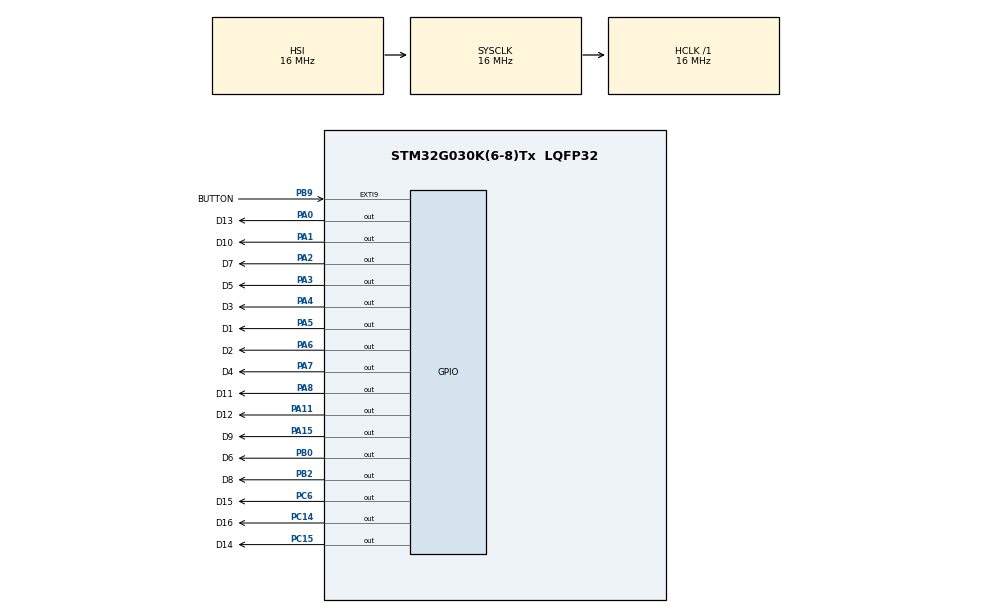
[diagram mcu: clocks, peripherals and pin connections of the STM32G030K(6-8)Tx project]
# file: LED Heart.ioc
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Mcu.Family=STM32G0
Mcu.Name=STM32G030K(6-8)Tx
Mcu.Package=LQFP32
NVIC.EXTI4_15_IRQn=true\:1\:0\:true\:false\:true\:true\:true\:true
NVIC.TIM1_BRK_UP_TRG_COM_IRQn=true\:2\:0\:true\:false\:true\:true\:true\:true
PA0.GPIO_Label=D13
PA0.Signal=GPIO_Output
PA1.GPIO_Label=D10
PA1.Signal=GPIO_Output
PA11\ [PA9].GPIO_Label=D12
PA11\ [PA9].Signal=GPIO_Output
PA15.GPIO_Label=D9
PA15.Signal=GPIO_Output
PA2.GPIO_Label=D7
PA2.Signal=GPIO_Output
PA3.GPIO_Label=D5
PA3.Signal=GPIO_Output
PA4.GPIO_Label=D3
PA4.Signal=GPIO_Output
PA5.GPIO_Label=D1
PA5.Signal=GPIO_Output
PA6.GPIO_Label=D2
PA6.Signal=GPIO_Output
PA7.GPIO_Label=D4
PA7.Signal=GPIO_Output
PA8.GPIO_Label=D11
PA8.Signal=GPIO_Output
PB0.GPIO_Label=D6
PB0.Signal=GPIO_Output
PB2.GPIO_Label=D8
PB2.Signal=GPIO_Output
PB9.GPIO_Label=BUTTON
PB9.GPIO_ModeDefaultEXTI=GPIO_MODE_IT_FALLING
PB9.GPIO_PuPd=GPIO_PULLUP
PB9.Signal=GPXTI9
PC14-OSC32_IN\ (PC14).GPIO_Label=D16
PC14-OSC32_IN\ (PC14).Signal=GPIO_Output
PC15-OSC32_OUT\ (PC15).GPIO_Label=D14
PC15-OSC32_OUT\ (PC15).Signal=GPIO_Output
PC6.GPIO_Label=D15
PC6.Signal=GPIO_Output
ProjectManager.HeapSize=0x200
ProjectManager.StackSize=0x400
ProjectManager.TargetToolchain=STM32CubeIDE
RCC.AHBFreq_Value=16000000
RCC.CortexFreq_Value=16000000
RCC.EXTERNAL_CLOCK_VALUE=12288000
RCC.HCLKFreq_Value=16000000
RCC.HSE_VALUE=8000000
RCC.HSI_VALUE=16000000
RCC.LSE_VALUE=32768
RCC.SYSCLKFreq_VALUE=16000000
RCC.VCOOutputFreq_Value=128000000
TIM1.Period=99
TIM1.Prescaler=15
VP_TIM1_VS_ClockSourceINT.Mode=Internal
board=custom

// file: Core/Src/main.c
/* USER CODE BEGIN Header */
/**
  ******************************************************************************
  * @file           : main.c
  * @brief          : Main program body
  ******************************************************************************
  * @attention
  *
  * Copyright (c) 2026 STMicroelectronics.
  * All rights reserved.
  *
  * This software is licensed under terms that can be found in the LICENSE file
  * in the root directory of this software component.
  * If no LICENSE file comes with this software, it is provided AS-IS.
  *
  ******************************************************************************
  */
/* USER CODE END Header */
#include "main.h"
#include "tim.h"
#include "gpio.h"

/* USER CODE BEGIN Includes */
#include "led_effect.h"
/* USER CODE END Includes */

void SystemClock_Config(void);

int main(void)
{

  /* MCU Configuration--------------------------------------------------------*/

  /* Reset of all peripherals, Initializes the Flash interface and the Systick. */
  HAL_Init();

  /* Configure the system clock */
  SystemClock_Config();

  /* Initialize all configured peripherals */
  MX_GPIO_Init();
  MX_TIM1_Init();
  /* USER CODE BEGIN 2 */
  HAL_TIM_Base_Start_IT(&htim1);
  /* USER CODE END 2 */

  /* Infinite loop */
  /* USER CODE BEGIN WHILE */
  while (1)
  {
	LED_Process_State();
	LED_Handler();

    /* USER CODE END WHILE */

  }
}

void SystemClock_Config(void)
{
  RCC_OscInitTypeDef RCC_OscInitStruct = {0};
  RCC_ClkInitTypeDef RCC_ClkInitStruct = {0};

  /** Configure the main internal regulator output voltage
  */
  HAL_PWREx_ControlVoltageScaling(PWR_REGULATOR_VOLTAGE_SCALE1);

  /** Initializes the RCC Oscillators according to the specified parameters
  * in the RCC_OscInitTypeDef structure.
  */
  RCC_OscInitStruct.OscillatorType = RCC_OSCILLATORTYPE_HSI;
  RCC_OscInitStruct.HSIState = RCC_HSI_ON;
  RCC_OscInitStruct.HSIDiv = RCC_HSI_DIV1;
  RCC_OscInitStruct.HSICalibrationValue = RCC_HSICALIBRATION_DEFAULT;
  RCC_OscInitStruct.PLL.PLLState = RCC_PLL_NONE;
  if (HAL_RCC_OscConfig(&RCC_OscInitStruct) != HAL_OK)
  {
    Error_Handler();
  }

  /** Initializes the CPU, AHB and APB buses clocks
  */
  RCC_ClkInitStruct.ClockType = RCC_CLOCKTYPE_HCLK|RCC_CLOCKTYPE_SYSCLK
                              |RCC_CLOCKTYPE_PCLK1;
  RCC_ClkInitStruct.SYSCLKSource = RCC_SYSCLKSOURCE_HSI;
  RCC_ClkInitStruct.AHBCLKDivider = RCC_SYSCLK_DIV1;
  RCC_ClkInitStruct.APB1CLKDivider = RCC_HCLK_DIV1;

  if (HAL_RCC_ClockConfig(&RCC_ClkInitStruct, FLASH_LATENCY_0) != HAL_OK)
  {
    Error_Handler();
  }
}

/* USER CODE BEGIN 4 */
void HAL_GPIO_EXTI_Falling_Callback(uint16_t GPIO_Pin)
{
    /* Button handling */
	if (GPIO_Pin == GPIO_PIN_9)
	{
		static uint32_t last_click_time = 0;
		if (HAL_GetTick() - last_click_time > 200)
		{
			last_click_time = HAL_GetTick();
			LED_Next_State();
		}
	}
}

void HAL_TIM_PeriodElapsedCallback(TIM_HandleTypeDef * htim)
{
  if (htim->Instance == TIM1)
  {
	  PWM_Flag_SetActive();
  }
}
/* USER CODE END 4 */

void Error_Handler(void)
{
  __disable_irq();
  while (1)
  {
  }
}
